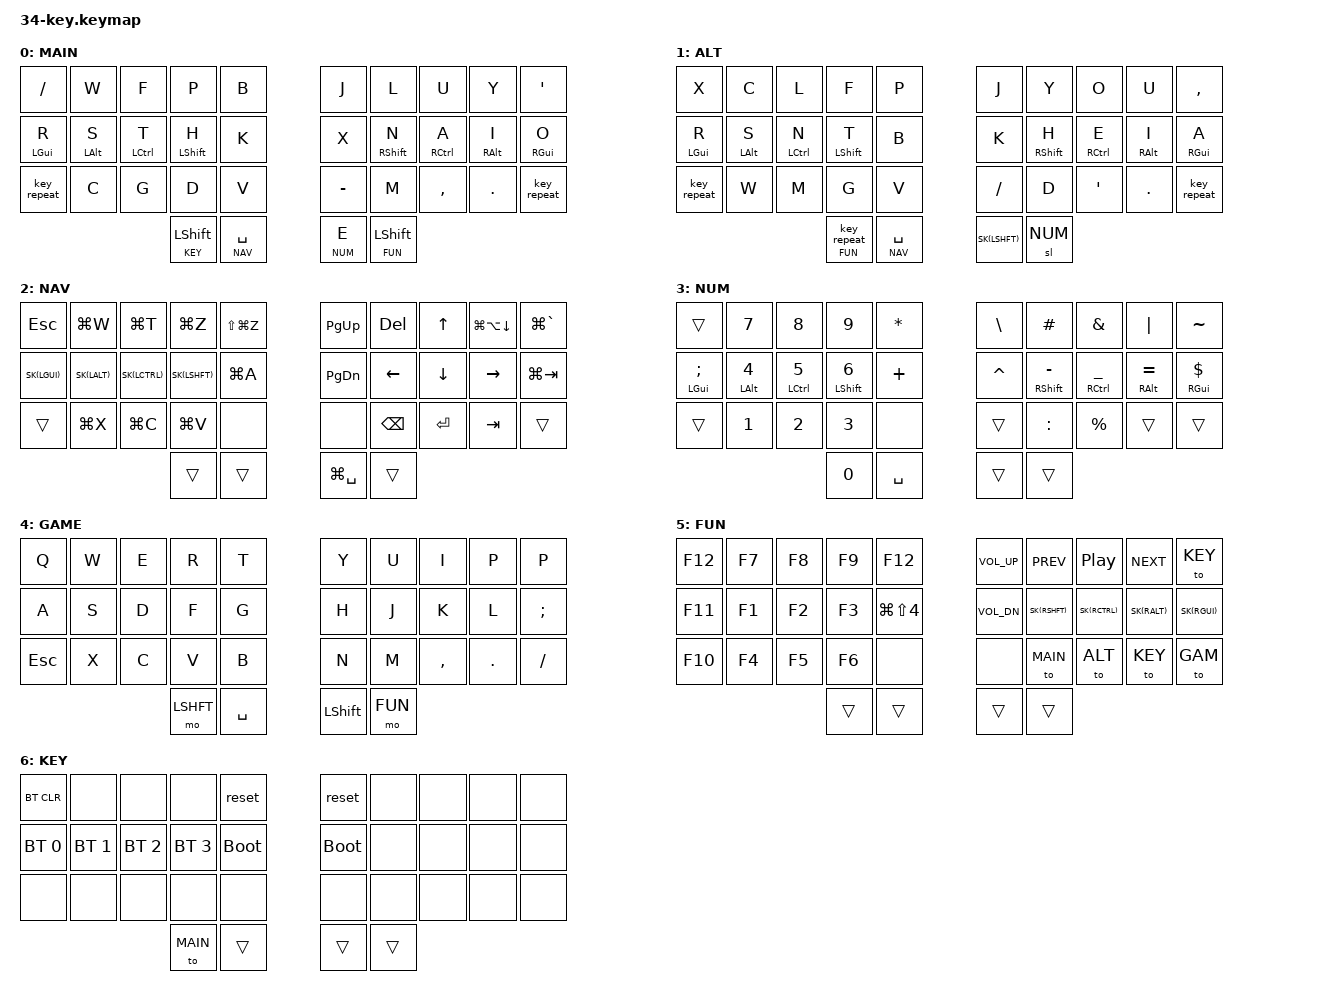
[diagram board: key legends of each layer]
#include <behaviors.dtsi>
#include <dt-bindings/zmk/keys.h>
#include <dt-bindings/zmk/bt.h>
#include <dt-bindings/zmk/outputs.h>


// Layer aliases
#define MAIN  0
#define ALT   1
#define NAV   2
#define NUM   3
#define GAM   4
#define FUN   5
#define KEY   6

// Desktop and tab navigation shortcuts
#define SS_TARGETED &kp LG(LS(N4))
#define SS_FULL     &kp LG(LS(N3))
#define WIN_LEFT    &kp LA(LC(LEFT))
#define WIN_RIGHT   &kp LA(LC(RIGHT))
#define WIN_FULL    &kp LA(LC(RET))
#define SELECT_ALL  &kp LG(A)
#define NEW_TAB     &kp LG(T)
#define FIND        &kp LG(F)
#define COMMAND     &kp LG(K)
#define U_UNDO      &kp LG(Z)
#define U_REDO      &kp LS(LG(Z))
#define U_PST       &kp LG(V)
#define U_CPY       &kp LG(C)
#define U_CUT       &kp LG(X)
#define QUIT        &kp LG(Q)
#define CLOSE       &kp LG(W)
#define APP_SWAP    &kp LG(TAB)
#define WIN_SWAP    &kp LG(GRAVE)
#define ALFRED      &kp LG(SPC)
#define DUPLICATE   &kp LG(D)
#define CLIP   &kp LG(LA(DOWN))

#define SK(KEY) &nk KEY KEY

/* Key Position Groups */
#define KEYS_L 0 1 2 3 4 10 11 12 13 14 20 21 22 23 24  // left-hand keys
#define KEYS_R 5 6 7 8 9 15 16 17 18 19 25 26 27 28 29  // right-hand keys
#define THUMBS 30 31 32 33                    // thumb keys

/* Behavior Settings */
&sl {
  release-after-ms = <250>;
};

&sk {
  release-after-ms = <60000>;
  quick-release;
};

&caps_word {
    continue-list = <BACKSPACE UNDERSCORE MINUS N1 N2 N3 N4 N5 N6 N7 N8 N9 N0>;
};

&lt {
 tapping-term-ms = <175>;
 flavor = "balanced";
};

&mt {
 tapping-term-ms = <175>;
 flavor = "tap-preferred";
};

// / {
//     conditional_layers {
//         compatible = "zmk,conditional-layers";
//         tri_layer {
//             if-layers = <3 4>;
//             then-layer = <5>;
//         };
//     };
// };

/ { 
    macros {
        codeblock: codeblock {
            compatible = "zmk,behavior-macro";
            #binding-cells = <0>;
            wait-ms = <0>;
            tap-ms = <0>;
            bindings = <&macro_tap &kp GRAVE &kp GRAVE &kp GRAVE>;
        };

        func: func {
            compatible = "zmk,behavior-macro";
            #binding-cells = <0>;
            wait-ms = <0>;
            tap-ms = <0>;
            bindings = <&macro_tap &kp EQUAL &kp GT>;
        };

        you: you {
            compatible = "zmk,behavior-macro";
            #binding-cells = <0>;
            wait-ms = <0>;
            tap-ms = <0>;
            bindings = <&macro_tap &kp Y &kp O &kp U>;
        };

        yeah: yeah {
            compatible = "zmk,behavior-macro";
            #binding-cells = <0>;
            wait-ms = <0>;
            tap-ms = <0>;
            bindings = <&macro_tap &kp Y &kp E &kp A &kp H>;
        };

        mo_nav: mo_nav {
            compatible = "zmk,behavior-macro";
            #binding-cells = <0>;
            wait-ms = <0>;
            tap-ms = <0>;
            bindings
                = <&macro_tap &kp K_CANCEL>
                , <&macro_press &mo NAV>
                , <&macro_pause_for_release>
                , <&macro_release &mo NAV>;
        };
    };

    behaviors {

        // ZMK_MACRO(mo_sym,
        //     wait-ms = <0>;
        //     tap-ms = <0>;
        //     bindings
        //     = <&macro_tap &kp K_CANCEL>
        //     , <&macro_press &mo SYM>
        //     , <&macro_pause_for_release>
        //     , <&macro_release &mo SYM>;
        // )

          hml: home-row-left {
            compatible = "zmk,behavior-hold-tap";
            label = "HOME_ROW_LEFT";
            #binding-cells = <2>;
            flavor = "balanced";
            tapping-term-ms = <280>;
            quick-tap-ms = <175>;                // double tapping same key allows for repeating
            global-quick-tap-ms = <60>;         // without PR #1387 use global-quick-tap instead
            bindings = <&kp>, <&kp>;
            hold-trigger-key-positions = <KEYS_R THUMBS>;
            hold-trigger-on-release;             // requires PR #1423
        };

        hmr: home-row-right {
            compatible = "zmk,behavior-hold-tap";
            label = "HOME_ROW_RIGHT";
            #binding-cells = <2>;
            flavor = "balanced";
            tapping-term-ms = <280>;
            quick-tap-ms = <175>;                // double tapping same key allows for repeating
            global-quick-tap-ms = <60>;         // without PR #1387 use global-quick-tap instead
            bindings = <&kp>, <&kp>;
            hold-trigger-key-positions = <KEYS_L THUMBS>;
            hold-trigger-on-release;             // requires PR #1423
        };

        as: alpha_shift {
            compatible = "zmk,behavior-hold-tap";
            label = "ALPHA_SFT";
            #binding-cells = <2>;
            tapping-term-ms = <170>;
            quick-tap-ms = <100>;
            flavor = "tap-preferred";
            bindings = <&kp>, <&kp>;
        };

        // Sticky key on tap, normal key on hold
        // Useful for modifier-clicking without the modifier remaining active
        nk: not_so_sticky_key {
            compatible = "zmk,behavior-hold-tap";
            label = "NOT_SO_STICKY_KEY";
            #binding-cells = <2>;
            tapping_term_ms = <200>;
            flavor = "tap-preferred";
            bindings = <&kp>, <&sk>;
        };

        lst: layer_sticky_tap {
            compatible = "zmk,behavior-hold-tap";
            label = "LAYER_STICKY_TAP";
            #binding-cells = <2>;
            tapping-term-ms = <200>;
            quick_tap_ms = <0>;
            flavor = "tap-preferred";
            bindings = <&mo>, <&sk>;
        };

        lr: layer_repeat {
            compatible = "zmk,behavior-hold-tap";
            label = "LAYER_REPEAT";
            #binding-cells = <2>;
            tapping_term_ms = <200>;
            quick-tap-ms = <175>;
            flavor = "balanced";
            bindings = <&mo>, <&key_repeat>;
        };

        lc: layer_caps {
            compatible = "zmk,behavior-hold-tap";
            label = "LAYER_CAPS";
            #binding-cells = <2>;
            tapping_term_ms = <200>;
            quick-tap-ms = <175>;
            flavor = "balanced";
            bindings = <&mo>, <&caps_word>;
        };

        dotexcl: dot_excl {
            compatible = "zmk,behavior-mod-morph";
            label = "DOT_EXCL";
            #binding-cells = <0>;
            bindings = <&kp DOT>, <&kp EXCL>;
            mods = <(MOD_LSFT|MOD_RSFT)>;
        };
    };

    keymap {
        compatible = "zmk,keymap";
// / w f p b         j l u y '
// r s t h k         x n a i o
// ⟳ c g d v         - m , . ⟳
//                   e

    main_layer {
            label = "MAIN";
            bindings = <
// ╭─────────────┬─────────────┬─────────────┬─────────────┬─────────────╮   ╭─────────────┬─────────────┬─────────────┬─────────────┬─────────────╮
     &kp SLASH     &kp W         &kp F         &kp P         &kp B             &kp J         &kp L         &kp U         &kp Y         &kp SQT
// ├────────────┼─────────────┼─────────────┼─────────────┼─────────────┤    ├─────────────┼─────────────┼─────────────┼─────────────┼─────────────┤
     &hml LGUI R   &hml LALT S   &hml LCTRL T  &hml LSHFT H  &kp K             &kp X         &hmr RSHFT N  &hmr RCTRL A  &hmr RALT I   &hmr RGUI O     
// ├─────────────┼─────────────┼─────────────┼─────────────┼─────────────┤   ├─────────────┼─────────────┼─────────────┼─────────────┼─────────────┤
     &key_repeat   &kp C         &kp G         &kp D         &kp V             &kp MINUS     &kp M         &kp COMMA     &kp DOT       &key_repeat
// ╰─────────────┴─────────────┴─────────────┼─────────────┼─────────────┤   ├─────────────┼─────────────┼─────────────┴─────────────┴─────────────╯
                                               &lst KEY LSHFT  &lt NAV SPACE   &lt NUM E     &lst FUN LSHFT
//                             ╰─────────────┴─────────────┴─────────────╯   ╰─────────────┴─────────────┴─────────────╯
        >;
    };

// w c y f k         j l o u '
// r s t h d         x n e i o
// ⟳ v g p b         - m / , .

    alt_layer {
            label = "ALT";
            bindings = <
// ╭─────────────┬─────────────┬─────────────┬─────────────┬─────────────╮   ╭─────────────┬─────────────┬─────────────┬─────────────┬─────────────╮
     &kp X         &kp C         &kp L         &kp F         &kp P             &kp J         &kp Y         &kp O         &kp U         &kp COMMA
// ├─────────────┼─────────────┼─────────────┼─────────────┼─────────────┤   ├─────────────┼─────────────┼─────────────┼─────────────┼─────────────┤
     &hml LGUI R   &hml LALT S   &hml LCTRL N  &hml LSHFT T  &kp B             &kp K         &hmr RSHFT H  &hmr RCTRL E  &hmr RALT I   &hmr RGUI A      
// ├─────────────┼─────────────┼─────────────┼─────────────┼─────────────┤   ├─────────────┼─────────────┼─────────────┼─────────────┼─────────────┤
     &key_repeat   &kp W         &kp M         &kp G         &kp V             &kp SLASH     &kp D         &kp SQT       &kp DOT       &key_repeat   
// ╰─────────────┴─────────────┴─────────────┼─────────────┼─────────────┤   ├─────────────┼─────────────┼─────────────┴─────────────┴─────────────╯
                                              &lr FUN 0     &lt NAV SPACE      SK(LSHFT)    &sl NUM
//                             ╰─────────────┴─────────────┴─────────────╯   ╰─────────────┴─────────────┴─────────────╯
        >;
    };

    nav_layer {
            label = "NAV";
            bindings = <
// ╭─────────────┬─────────────┬─────────────┬─────────────┬─────────────╮   ╭─────────────┬─────────────┬─────────────┬─────────────┬─────────────╮
     &kp ESC       CLOSE         NEW_TAB       U_UNDO        U_REDO            &kp PG_UP     &kp DEL       &kp UP        CLIP          WIN_SWAP
// ├─────────────┼─────────────┼─────────────┼─────────────┼─────────────┤   ├─────────────┼─────────────┼─────────────┼─────────────┼────────────┤
     SK(LGUI)      SK(LALT)      SK(LCTRL)     SK(LSHFT)     SELECT_ALL        &kp PG_DN     &kp LEFT      &kp DOWN      &kp RIGHT     APP_SWAP        
// ├─────────────┼─────────────┼─────────────┼─────────────┼─────────────┤   ├─────────────┼─────────────┼─────────────┼─────────────┼─────────────┤
     &trans        U_CUT         U_CPY         U_PST         &none             &none         &kp BSPC      &kp RET       &kp TAB       &trans                    
// ╰─────────────┴─────────────┴─────────────┼─────────────┼─────────────┤   ├─────────────┼─────────────┼─────────────┴─────────────┴─────────────╯
                                               &trans        &trans            ALFRED        &trans
//                             ╰─────────────┴─────────────┴─────────────╯   ╰─────────────┴─────────────┴─────────────╯
            >;
        };

        num_layer { 
            label = "NUM";
            bindings = < 
// ╭─────────────┬─────────────┬─────────────┬─────────────┬─────────────╮   ╭─────────────┬─────────────┬─────────────┬─────────────┬─────────────╮
     &trans         &kp N7        &kp N8       &kp N9        &kp STAR          &kp BSLH      &kp HASH      &kp AMPS      &kp PIPE      &kp TILDE
// ├─────────────┼─────────────┼─────────────┼─────────────┼ ────────────┤   ├──────────────┼─────────────┼─────────────┼─────────────┼─────────────┤
     &hml LGUI SEMICOLON &hml LALT N4  &hml LCTRL N5 &hml LSHFT N6 &kp PLUS    &kp CARET     &hmr RSHFT MINUS &hmr RCTRL UNDER &hmr RALT EQUAL &hmr RGUI DOLLAR
// ├─────────────┼─────────────┼─────────────┼─────────────┼─────────────┤   ├─────────────┼─────────────┼─────────────┼─────────────┼─────────────┤
     &trans         &kp N1        &kp N2       &kp N3        &none             &trans        &kp COLON     &kp PERCENT   &trans         &trans        
// ╰─────────────┴─────────────┴─────────────┼─────────────┼─────────────┤   ├─────────────┼─────────────┼─────────────┴─────────────┴─────────────╯
                                                &kp N0       &kp SPACE         &trans        &trans
//                             ╰─────────────┴─────────────┴─────────────╯   ╰─────────────┴─────────────┴─────────────╯
            >;
        };

        game_layer {
            label = "GAME";
            bindings = <
// ╭─────────────┬─────────────┬─────────────┬─────────────┬─────────────╮   ╭─────────────┬─────────────┬─────────────┬─────────────┬─────────────╮
     &kp Q         &kp W         &kp E         &kp R         &kp T             &kp Y         &kp U         &kp I         &kp P         &kp P
// ├─────────────┼─────────────┼─────────────┼─────────────┼─────────────┤   ├─────────────┼─────────────┼─────────────┼─────────────┼─────────────┤
     &kp A         &kp S         &kp D         &kp F         &kp G             &kp H         &kp J         &kp K         &kp L         &kp SEMICOLON      
// ├─────────────┼─────────────┼─────────────┼─────────────┼─────────────┤   ├─────────────┼─────────────┼─────────────┼─────────────┼─────────────┤
     &kp ESC       &kp X         &kp C         &kp V         &kp B             &kp N         &kp M         &kp COMMA     &kp DOT       &kp SLASH   
// ╰─────────────┴─────────────┴─────────────┼─────────────┼─────────────┤   ├─────────────┼─────────────┼─────────────┴─────────────┴─────────────╯
                                              &mo LSHFT      &kp SPACE         &kp LSHFT     &mo FUN 
//                             ╰─────────────┴─────────────┴─────────────╯   ╰─────────────┴─────────────┴─────────────╯
            >;
        };

        function_layer { 
            label = "FUN";
            bindings = <
// ╭─────────────┬─────────────┬─────────────┬─────────────┬─────────────╮   ╭─────────────┬─────────────┬─────────────┬─────────────┬─────────────╮
     &kp F12       &kp F7        &kp F8        &kp F9        &kp F12           &kp C_VOL_UP  &kp C_PREV    &kp C_PP      &kp C_NEXT    &to KEY
// ├─────────────┼───────────┼─────────────┼───────────────┼─────────────┤   ├─────────────┼─────────────┼─────────────┼─────────────┼─────────────┤
     &kp F11       &kp F1        &kp F2        &kp F3        SS_TARGETED       &kp C_VOL_DN  SK(RSHFT)     SK(RCTRL)     SK(RALT)      SK(RGUI)
// ├─────────────┼───────────┼─────────────┼───────────────┼─────────────┤   ├─────────────┼─────────────┼─────────────┼─────────────┼─────────────┤
     &kp F10       &kp F4        &kp F5        &kp F6        &none             &none         &to MAIN      &to ALT       &to KEY       &to GAM              
// ├─────────────┼─────────────┼─────────────┴─────────────┴─────────────╯   ├─────────────┼─────────────┼─────────────┴─────────────┴─────────────╯
                                               &trans        &trans            &trans        &trans             
//                             ╰─────────────┴─────────────┴─────────────╯   ╰─────────────┴─────────────┴─────────────╯
            >;
        };

        keyboard_layer {
            label = "KEY";
            bindings = <
// ╭─────────────┬─────────────┬─────────────┬─────────────┬─────────────╮   ╭─────────────┬─────────────┬─────────────┬─────────────┬─────────────╮
     &bt BT_CLR    &none         &none         &none         &reset             &reset        &none        &none        &none        &none
// ├─────────────┼─────────────┼─────────────┼─────────────┼─────────────┤   ├─────────────┼───────────┼─────────────┼───────────────┼─────────────┤
     &bt BT_SEL 0  &bt BT_SEL 1  &bt BT_SEL 2  &bt BT_SEL 3  &bootloader        &bootloader   &none        &none        &none        &none
// ├─────────────┼─────────────┼─────────────┼─────────────┼─────────────┤   ├─────────────┼───────────┼─────────────┼───────────────┼─────────────┤
     &none         &none         &none         &none         &none              &none         &none        &none        &none          &none           
// ├─────────────┼─────────────┼─────────────┴─────────────┴─────────────╯   ├─────────────┼─────────────┼─────────────┴─────────────┴─────────────╯
                                               &to MAIN      &trans             &trans        &trans
//                             ╰─────────────┴─────────────┴─────────────╯   ╰─────────────┴─────────────┴─────────────╯
            >;
        };
    };
};

#include "34-key-combos.dtsi" 
